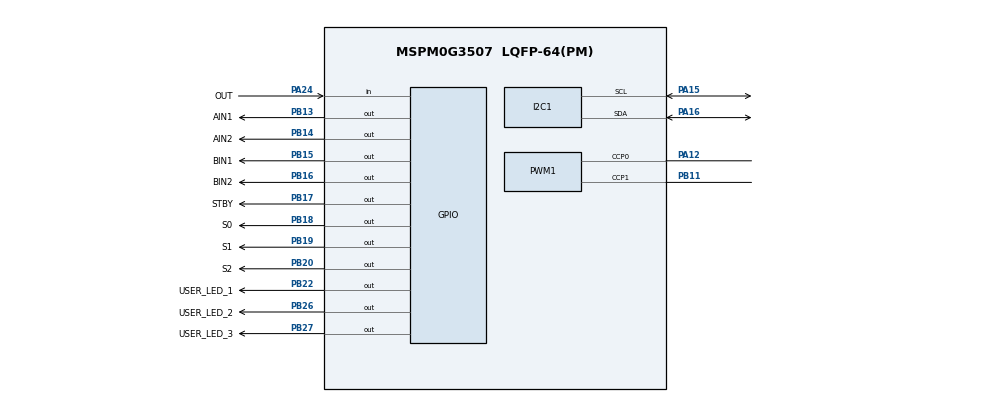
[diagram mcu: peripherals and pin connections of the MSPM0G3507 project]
/**
 * These arguments were used when this file was generated. They will be automatically applied on subsequent loads
 * via the GUI or CLI. Run CLI with '--help' for additional information on how to override these arguments.
 * @cliArgs --device "MSPM0G350X" --part "Default" --package "LQFP-64(PM)" --product "mspm0_sdk@2.10.00.04"
 * @v2CliArgs --device "MSPM0G3507" --package "LQFP-64(PM)" --product "mspm0_sdk@2.10.00.04"
 * @versions {"tool":"1.26.2+4477"}
 */

/**
 * Import the modules used in this configuration.
 */
const GPIO   = scripting.addModule("/ti/driverlib/GPIO", {}, false);
const GPIO1  = GPIO.addInstance();
const GPIO2  = GPIO.addInstance();
const GPIO3  = GPIO.addInstance();
const I2C    = scripting.addModule("/ti/driverlib/I2C", {}, false);
const I2C1   = I2C.addInstance();
const PWM    = scripting.addModule("/ti/driverlib/PWM", {}, false);
const PWM1   = PWM.addInstance();
const SYSCTL = scripting.addModule("/ti/driverlib/SYSCTL");
const TIMER  = scripting.addModule("/ti/driverlib/TIMER", {}, false);
const TIMER1 = TIMER.addInstance();

/**
 * Write custom configuration values to the imported modules.
 */
GPIO1.$name                         = "GPIO_LEDS";
GPIO1.associatedPins.create(3);
GPIO1.associatedPins[0].$name       = "USER_LED_1";
GPIO1.associatedPins[0].pin.$assign = "PB22";
GPIO1.associatedPins[1].$name       = "USER_LED_2";
GPIO1.associatedPins[1].pin.$assign = "PB26";
GPIO1.associatedPins[2].$name       = "USER_LED_3";
GPIO1.associatedPins[2].pin.$assign = "PB27";

const Board = scripting.addModule("/ti/driverlib/Board", {}, false);

GPIO2.$name                         = "GPIO_MOTOR";
GPIO2.associatedPins.create(5);
GPIO2.associatedPins[0].$name       = "AIN1";
GPIO2.associatedPins[0].pin.$assign = "PB13";
GPIO2.associatedPins[1].$name       = "AIN2";
GPIO2.associatedPins[1].pin.$assign = "PB14";
GPIO2.associatedPins[2].$name       = "BIN1";
GPIO2.associatedPins[2].pin.$assign = "PB15";
GPIO2.associatedPins[3].$name       = "BIN2";
GPIO2.associatedPins[3].pin.$assign = "PB16";
GPIO2.associatedPins[4].$name       = "STBY";
GPIO2.associatedPins[4].pin.$assign = "PB17";

GPIO3.$name                         = "GPIO_SENSOR";
GPIO3.associatedPins.create(4);
GPIO3.associatedPins[0].$name       = "S0";
GPIO3.associatedPins[0].pin.$assign = "PB18";
GPIO3.associatedPins[1].$name       = "S1";
GPIO3.associatedPins[1].pin.$assign = "PB19";
GPIO3.associatedPins[2].$name       = "S2";
GPIO3.associatedPins[2].pin.$assign = "PB20";
GPIO3.associatedPins[3].$name       = "OUT";
GPIO3.associatedPins[3].direction   = "INPUT";
GPIO3.associatedPins[3].pin.$assign = "PA24";

I2C1.$name                     = "I2C_0";
I2C1.peripheral.sdaPin.$assign = "PA16";
I2C1.peripheral.sclPin.$assign = "PA15";
I2C1.sdaPinConfig.$name        = "ti_driverlib_gpio_GPIOPinGeneric2";
I2C1.sclPinConfig.$name        = "ti_driverlib_gpio_GPIOPinGeneric3";

PWM1.$name                              = "PWM_MOTOR";
PWM1.pwmMode                            = "EDGE_ALIGN_UP";
PWM1.timerCount                         = 2000;
PWM1.peripheral.$assign                 = "TIMG0";
PWM1.peripheral.ccp0Pin.$assign         = "PA12";
PWM1.peripheral.ccp1Pin.$assign         = "PB11";
PWM1.PWM_CHANNEL_0.$name                = "ti_driverlib_pwm_PWMTimerCC0";
PWM1.PWM_CHANNEL_1.$name                = "ti_driverlib_pwm_PWMTimerCC1";
PWM1.ccp0PinConfig.direction            = scripting.forceWrite("OUTPUT");
PWM1.ccp0PinConfig.hideOutputInversion  = scripting.forceWrite(false);
PWM1.ccp0PinConfig.onlyInternalResistor = scripting.forceWrite(false);
PWM1.ccp0PinConfig.passedPeripheralType = scripting.forceWrite("Digital");
PWM1.ccp0PinConfig.$name                = "ti_driverlib_gpio_GPIOPinGeneric0";
PWM1.ccp1PinConfig.direction            = scripting.forceWrite("OUTPUT");
PWM1.ccp1PinConfig.hideOutputInversion  = scripting.forceWrite(false);
PWM1.ccp1PinConfig.onlyInternalResistor = scripting.forceWrite(false);
PWM1.ccp1PinConfig.passedPeripheralType = scripting.forceWrite("Digital");
PWM1.ccp1PinConfig.$name                = "ti_driverlib_gpio_GPIOPinGeneric1";

SYSCTL.forceDefaultClkConfig = true;
SYSCTL.clockTreeEn           = true;

TIMER1.$name            = "TIMER_0";
TIMER1.interrupts       = ["ZERO"];
TIMER1.timerMode        = "PERIODIC";
TIMER1.timerPeriod      = "10 ms";
TIMER1.timerClkPrescale = 256;

/**
 * Pinmux solution for unlocked pins/peripherals. This ensures that minor changes to the automatic solver in a future
 * version of the tool will not impact the pinmux you originally saw.  These lines can be completely deleted in order to
 * re-solve from scratch.
 */
Board.peripheral.$suggestSolution          = "DEBUGSS";
Board.peripheral.swclkPin.$suggestSolution = "PA20";
Board.peripheral.swdioPin.$suggestSolution = "PA19";
I2C1.peripheral.$suggestSolution           = "I2C1";
TIMER1.peripheral.$suggestSolution         = "TIMA0";
